AUTOSAR XML (schema 4.0)
standard types defined: float32, float64, sint16, sint32, sint8, uint16, uint32, uint8, void, boolean
package /ImplDataTypes
  impl type MultiStateBtnType: implementation-data-type=uint8, type-emitter=RTE
  impl type StepMotorStepType: implementation-data-type=uint16, type-emitter=RTE
package /MappingSets
  data type mapping set MappingSet
package /PortInterfaces/ClientServer
  client server interface CsIf_StepMotor
    operation Move
      arg step: type=MultiStateBtnType, direction=IN
package /PortInterfaces/SenderReceiver
  sender receiver interface SrIf_SeatCtrlBtns
    data HeightBtnState: type=MultiStateBtnType
    data InclindeBtnState: type=MultiStateBtnType
    data SlideBtnState: type=MultiStateBtnType
  sender receiver interface SrIf_SeatCtrlData
    data Height: type=uint8
    data Inclinde: type=uint8
    data Slide: type=uint8
package /SoftwareComponents
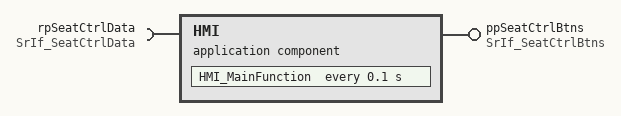
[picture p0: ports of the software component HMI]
  application sw component type HMI
    provide port ppSeatCtrlBtns: provided-interface=SrIf_SeatCtrlBtns
    require port rpSeatCtrlData: required-interface=SrIf_SeatCtrlData
    behavior Ibhv_HMI: data-type-mapping=MappingSet, handle-termination-and-restart=NO-SUPPORT
      timing event TE_HMI_MainFunction_100ms: start-on-event=HMI_MainFunction, period=0.1
      runnable HMI_MainFunction
        data-receive-point-by-arguments:
          access DRP_rpSeatCtrlData_Height: accessed-variable=rpSeatCtrlData.Height
          access DRP_rpSeatCtrlData_Inclinde: accessed-variable=rpSeatCtrlData.Inclinde
          access DRP_rpSeatCtrlData_Slide: accessed-variable=rpSeatCtrlData.Slide
        data-send-points:
          access DSP_ppSeatCtrlBtns_HeightBtnState: accessed-variable=ppSeatCtrlBtns.HeightBtnState
          access DSP_ppSeatCtrlBtns_InclindeBtnState: accessed-variable=ppSeatCtrlBtns.InclindeBtnState
          access DSP_ppSeatCtrlBtns_SlideBtnState: accessed-variable=ppSeatCtrlBtns.SlideBtnState
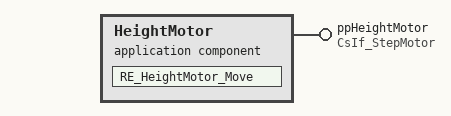
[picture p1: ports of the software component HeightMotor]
  application sw component type HeightMotor
    provide port ppHeightMotor: provided-interface=CsIf_StepMotor
    behavior Ibhv_HeightMotor: data-type-mapping=MappingSet, handle-termination-and-restart=NO-SUPPORT
      operation invoked event OIE_ppHeightMotor_Move: start-on-event=RE_HeightMotor_Move, operation=ppHeightMotor.Move
      runnable RE_HeightMotor_Move
  5 x swc implementation, all with programming-language=C, sw-version=1.0.0, vendor-id=255:
    Impl_HMI: behavior=Ibhv_HMI
      code-descriptors:
        code Code: artifact-descriptors=autosar-engineering-object={short-label=SWC.c, category=SWSRC}
      resource consumption ResourceConsumption
    Impl_HeightMotor: behavior=Ibhv_HeightMotor
      code-descriptors:
        code Code: artifact-descriptors=autosar-engineering-object={short-label=SWC.c, category=SWSRC}
      resource consumption ResourceConsumption
    Impl_InclineMotor: behavior=Ibhv_InclineMotor
      code-descriptors:
        code Code: artifact-descriptors=autosar-engineering-object={short-label=SWC.c, category=SWSRC}
      resource consumption ResourceConsumption
    Impl_SeatManager: behavior=Ibhv_SeatManager
      code-descriptors:
        code Code: artifact-descriptors=autosar-engineering-object={short-label=SWC.c, category=SWSRC}
      resource consumption ResourceConsumption
    Impl_SlideMotor: behavior=Ibhv_SlideMotor
      code-descriptors:
        code Code: artifact-descriptors=autosar-engineering-object={short-label=SWC.c, category=SWSRC}
      resource consumption ResourceConsumption
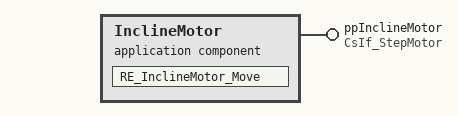
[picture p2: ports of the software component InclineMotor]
  application sw component type InclineMotor
    provide port ppInclineMotor: provided-interface=CsIf_StepMotor
    behavior Ibhv_InclineMotor: data-type-mapping=MappingSet, handle-termination-and-restart=NO-SUPPORT
      operation invoked event OIE_ppInclineMotor_Move: start-on-event=RE_InclineMotor_Move, operation=ppInclineMotor.Move
      runnable RE_InclineMotor_Move
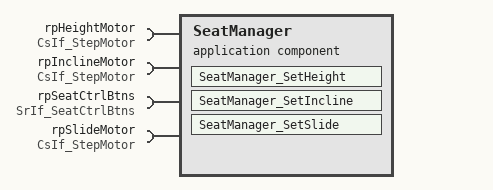
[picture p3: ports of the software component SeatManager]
  application sw component type SeatManager
    4 x require port:
      rpHeightMotor: required-interface=CsIf_StepMotor
      rpInclineMotor: required-interface=CsIf_StepMotor
      rpSeatCtrlBtns: required-interface=SrIf_SeatCtrlBtns
      rpSlideMotor: required-interface=CsIf_StepMotor
    behavior Ibhv_SeatManager: data-type-mapping=MappingSet, handle-termination-and-restart=NO-SUPPORT
      data received event DRE_rpSeatCtrlBtns_HeightBtnState: start-on-event=SeatManager_SetHeight, data=rpSeatCtrlBtns.HeightBtnState
      data received event DRE_rpSeatCtrlBtns_InclindeBtnState: start-on-event=SeatManager_SetIncline, data=rpSeatCtrlBtns.InclindeBtnState
      data received event DRE_rpSeatCtrlBtns_SlideBtnState: start-on-event=SeatManager_SetSlide, data=rpSeatCtrlBtns.SlideBtnState
      runnable SeatManager_SetHeight
        data-receive-point-by-arguments:
          access DRP_rpSeatCtrlBtns_HeightBtnState: accessed-variable=rpSeatCtrlBtns.HeightBtnState
        sync call SCP_ppHeightMotor_Move: operation=rpHeightMotor.Move, timeout=0.0
      runnable SeatManager_SetIncline
        data-receive-point-by-arguments:
          access DRP_rpSeatCtrlBtns_InclindeBtnState: accessed-variable=rpSeatCtrlBtns.InclindeBtnState
        sync call SCP_rpInclineMotor_Move: operation=rpInclineMotor.Move, timeout=0.0
      runnable SeatManager_SetSlide
        data-receive-point-by-arguments:
          access DRP_rpSeatCtrlBtns_SlideBtnState: accessed-variable=rpSeatCtrlBtns.SlideBtnState
        sync call SCP_rpSlideMotor_Move: operation=rpSlideMotor.Move, timeout=0.0
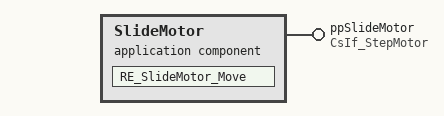
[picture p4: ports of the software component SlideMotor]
  application sw component type SlideMotor
    provide port ppSlideMotor: provided-interface=CsIf_StepMotor
    behavior Ibhv_SlideMotor: data-type-mapping=MappingSet, handle-termination-and-restart=NO-SUPPORT
      operation invoked event OIE_ppSlideMotor_Move: start-on-event=RE_SlideMotor_Move, operation=ppSlideMotor.Move
      runnable RE_SlideMotor_Move
package /Compositions
  composition sw component type TestAppComposition
    5 x component:
      HMI: type=HMI
      HeightMotor: type=HeightMotor
      InclineMotor: type=InclineMotor
      SeatManager: type=SeatManager
      SlideMotor: type=SlideMotor
    connect HMI.ppSeatCtrlBtns -> SeatManager.rpSeatCtrlBtns
    connect HeightMotor.ppHeightMotor -> SeatManager.rpHeightMotor
    connect InclineMotor.ppInclineMotor -> SeatManager.rpInclineMotor
    connect SlideMotor.ppSlideMotor -> SeatManager.rpSlideMotor
